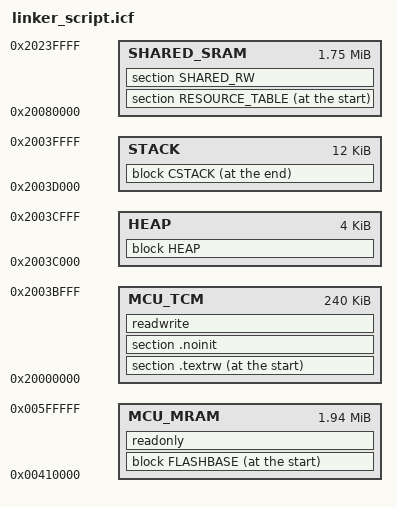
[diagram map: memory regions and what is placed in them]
//*****************************************************************************
//
// linker_script.icf
//
// IAR linker Configuration File
//
//*****************************************************************************

//
// Define a memory section that covers the entire 4 GB addressable space of the
// processor. (32-bit can address up to 4GB)
//
define memory mem with size = 4G;

//
// Define regions for the various types of internal memory.
//
define region MCU_MRAM    = mem:[from 0x00410000 to 0x005FFFFF];
define region MCU_TCM     = mem:[from 0x20000000 to 0x2003BFFF];
define region SHARED_SRAM = mem:[from 0x20080000 to 0x2023FFFF];
define region STACK       = mem:[from 0x2003D000 to 0x2003FFFF];
define region HEAP        = mem:[from 0x2003C000 to 0x2003CFFF];

//
// Define blocks for logical groups of data.
//
define block HEAP with alignment = 0x8, size = 4096
{
    section .heap
};
define block CSTACK with alignment = 0x8, size = 12288 
{
    section .stack
};

define block FLASHBASE with fixed order
{
    readonly section .intvec,
    readonly section .patch
};

//
// Set section properties.
//
initialize by copy { readwrite };
initialize by copy { section SHARED_RW };
do not initialize { section .noinit, section .stack , section .heap};
//
// Place code sections in memory regions.
//
place at start of MCU_MRAM { block FLASHBASE };
place in MCU_MRAM { readonly };
place at start of MCU_TCM { section .textrw };
place at end of STACK { block CSTACK};
place in HEAP { block HEAP};
place in MCU_TCM { section .noinit, readwrite};
place at start of SHARED_SRAM { section RESOURCE_TABLE };
place in SHARED_SRAM { section SHARED_RW };
